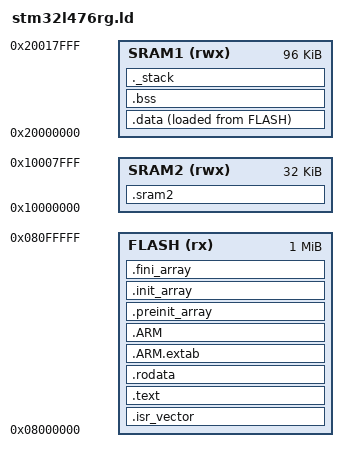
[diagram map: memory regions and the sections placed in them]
/* Linker script for STM32L476RG (NUCLEO-L476RG)
 * Flash: 1024K, SRAM1: 96K, SRAM2: 32K
 */

MEMORY
{
    FLASH  (rx)  : ORIGIN = 0x08000000, LENGTH = 1024K
    SRAM1  (rwx) : ORIGIN = 0x20000000, LENGTH = 96K
    SRAM2  (rwx) : ORIGIN = 0x10000000, LENGTH = 32K
}

/* Initial stack pointer at top of SRAM1 */
_estack = ORIGIN(SRAM1) + LENGTH(SRAM1);

ENTRY(Reset_Handler)

SECTIONS
{
    /* Vector table must be first in flash */
    .isr_vector :
    {
        . = ALIGN(4);
        KEEP(*(.isr_vector))
        . = ALIGN(4);
    } > FLASH

    /* Code */
    .text :
    {
        . = ALIGN(4);
        *(.text)
        *(.text*)
        *(.glue_7)
        *(.glue_7t)

        KEEP(*(.init))
        KEEP(*(.fini))

        . = ALIGN(4);
        _etext = .;
    } > FLASH

    /* Read-only data */
    .rodata :
    {
        . = ALIGN(4);
        *(.rodata)
        *(.rodata*)
        . = ALIGN(4);
    } > FLASH

    /* ARM exception unwind tables */
    .ARM.extab :
    {
        *(.ARM.extab* .gnu.linkonce.armextab.*)
    } > FLASH

    .ARM :
    {
        __exidx_start = .;
        *(.ARM.exidx*)
        __exidx_end = .;
    } > FLASH

    /* C++ constructors */
    .preinit_array :
    {
        PROVIDE_HIDDEN(__preinit_array_start = .);
        KEEP(*(.preinit_array*))
        PROVIDE_HIDDEN(__preinit_array_end = .);
    } > FLASH

    .init_array :
    {
        PROVIDE_HIDDEN(__init_array_start = .);
        KEEP(*(SORT(.init_array.*)))
        KEEP(*(.init_array*))
        PROVIDE_HIDDEN(__init_array_end = .);
    } > FLASH

    .fini_array :
    {
        PROVIDE_HIDDEN(__fini_array_start = .);
        KEEP(*(SORT(.fini_array.*)))
        KEEP(*(.fini_array*))
        PROVIDE_HIDDEN(__fini_array_end = .);
    } > FLASH

    /* Initialized data: LMA in flash, VMA in SRAM1 */
    _sidata = LOADADDR(.data);

    .data :
    {
        . = ALIGN(4);
        _sdata = .;
        *(.data)
        *(.data*)
        . = ALIGN(4);
        _edata = .;
    } > SRAM1 AT> FLASH

    /* Zero-initialized data */
    .bss :
    {
        . = ALIGN(4);
        _sbss = .;
        __bss_start__ = _sbss;
        *(.bss)
        *(.bss*)
        *(COMMON)
        . = ALIGN(4);
        _ebss = .;
        __bss_end__ = _ebss;
    } > SRAM1

    /* SRAM2 for overflow (large solver workspace) */
    .sram2 (NOLOAD) :
    {
        . = ALIGN(4);
        *(.sram2)
        *(.sram2*)
        . = ALIGN(4);
    } > SRAM2

    /* Ensure stack doesn't collide with BSS */
    ._stack :
    {
        . = ALIGN(8);
        PROVIDE(_end = .);
        . = . + 2048;  /* Minimum 2KB stack guard */
        . = ALIGN(8);
    } > SRAM1
}
